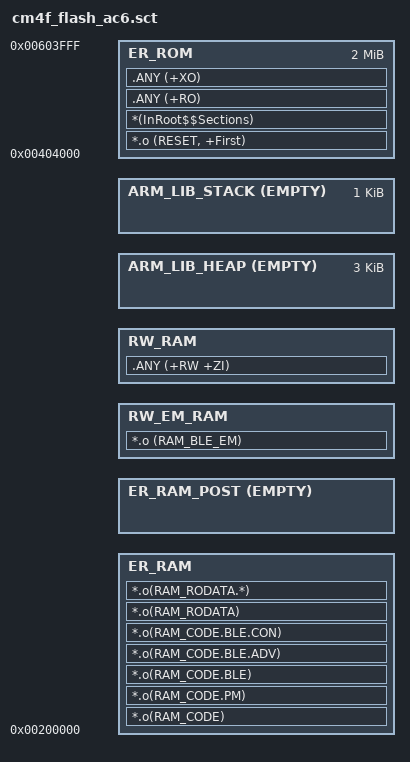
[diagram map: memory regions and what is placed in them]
#! armclang -E --target=arm-arm-none-eabi -mcpu=cortex-m4 -xc
; command above MUST be in first line (no comment above!)

/*
;-------- <<< Use Configuration Wizard in Context Menu >>> -------------------
*/

/*--------------------- Flash Configuration ----------------------------------
; <h> Flash Configuration
;   <o0> Flash Base Address <0x404000-0x600000:8>
;   <o1> Flash Size (in Bytes) <0x0-0x200000:8>
; </h>
 *----------------------------------------------------------------------------*/
#define __ROM_BASE      0x404000
#define __ROM_SIZE      0x200000

/*--------------------- Embedded RAM Configuration ---------------------------
; <h> RAM Configuration
;   <o0> RAM Base Address    <0x20000000-0x20020000:8>
;   <o1> RAM Size (in Bytes) <0x0-0x20000:8>
; </h>
 *----------------------------------------------------------------------------*/
#define __RAM_BASE      0x20000000
#define __RAM_SIZE      0x00040000

/*--------------------- Stack / Heap Configuration ---------------------------
; <h> Stack / Heap Configuration
;   <o0> Stack Size (in Bytes) <0x0-0x00020000:8>
;   <o1> Heap Size (in Bytes) <0x0-0x00020000:8>
; </h>
 *----------------------------------------------------------------------------*/
#define __STACK_SIZE    0x00000400
#define __HEAP_SIZE     0x00000C00

/*
;------------- <<< end of configuration section >>> ---------------------------
*/


/*----------------------------------------------------------------------------
  Scatter File Definitions definition
 *----------------------------------------------------------------------------*/
#define __RO_BASE       __ROM_BASE
#define __RO_SIZE       __ROM_SIZE

#define __RW_BASE       __RAM_BASE
#define __RW_SIZE      (__RAM_SIZE - __STACK_SIZE - __HEAP_SIZE)

#define __RAM_RO_BASE  (0x200000 + __RAM_BASE - 0x20000000)


LR_ROM __RO_BASE __RO_SIZE  {                       ; load region size_region
  ER_ROM __RO_BASE __RO_SIZE  {                     ; load address = execution address
   *.o (RESET, +First)
   *(InRoot$$Sections)
   .ANY (+RO)
   .ANY (+XO)
  }

  ER_RAM __RAM_RO_BASE ALIGN 4 {
    *.o(RAM_CODE)
    *.o(RAM_CODE.PM)
    *.o(RAM_CODE.BLE)
    *.o(RAM_CODE.BLE.ADV)
    *.o(RAM_CODE.BLE.CON)
    *.o(RAM_RODATA)
    *.o(RAM_RODATA.*)
  }
  ER_RAM_POST +0 ALIGN 32 EMPTY 0 {    ; Reserve 0 bytes region for ER_RAM
  }

  RW_EM_RAM __RW_BASE + ImageLimit(ER_RAM_POST) - ImageBase(ER_RAM) {   ; EM data
   *.o (RAM_BLE_EM)
  }

  RW_RAM +0 ALIGN 4 {   ; RW data
   .ANY (+RW +ZI)
  }

#if __HEAP_SIZE > 0
  ARM_LIB_HEAP  +0 ALIGN 8 EMPTY  __HEAP_SIZE  {   ; Reserve empty region for heap
  }
#endif

  ARM_LIB_STACK +0 ALIGN 8 EMPTY __STACK_SIZE  {   ; Reserve empty region for stack
  }
}
